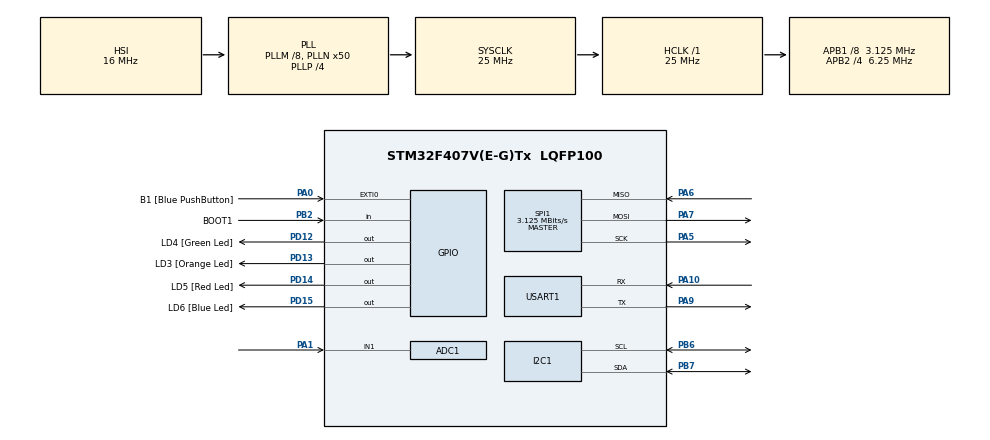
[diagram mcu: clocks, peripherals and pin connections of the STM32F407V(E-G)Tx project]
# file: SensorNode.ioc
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ADC1.Channel-0\#ChannelRegularConversion=ADC_CHANNEL_1
ADC1.NbrOfConversionFlag=1
ADC1.Rank-0\#ChannelRegularConversion=1
ADC1.SamplingTime-0\#ChannelRegularConversion=ADC_SAMPLETIME_3CYCLES
ADC1.master=1
Mcu.Family=STM32F4
Mcu.Name=STM32F407V(E-G)Tx
Mcu.Package=LQFP100
NVIC.PriorityGroup=NVIC_PRIORITYGROUP_0
PA0-WKUP.GPIO_Label=B1 [Blue PushButton]
PA0-WKUP.GPIO_ModeDefaultEXTI=GPIO_MODE_EVT_RISING
PA0-WKUP.GPIO_PuPd=GPIO_NOPULL
PA0-WKUP.Signal=GPXTI0
PA1.Signal=ADCx_IN1
PA10.Mode=Asynchronous
PA10.Signal=USART1_RX
PA13.GPIO_Label=SWDIO
PA13.Mode=Serial_Wire
PA13.Signal=SYS_JTMS-SWDIO
PA14.GPIO_Label=SWCLK
PA14.Mode=Serial_Wire
PA14.Signal=SYS_JTCK-SWCLK
PA5.Mode=Full_Duplex_Master
PA5.Signal=SPI1_SCK
PA6.Mode=Full_Duplex_Master
PA6.Signal=SPI1_MISO
PA7.Mode=Full_Duplex_Master
PA7.Signal=SPI1_MOSI
PA9.Mode=Asynchronous
PA9.Signal=USART1_TX
PB2.GPIO_Label=BOOT1
PB2.GPIO_Mode=GPIO_MODE_INPUT
PB2.GPIO_PuPd=GPIO_NOPULL
PB2.Signal=GPIO_Input
PB3.GPIO_Label=SWO
PB3.Signal=SYS_JTDO-SWO
PB6.Mode=I2C
PB6.Signal=I2C1_SCL
PB7.Mode=I2C
PB7.Signal=I2C1_SDA
PC14-OSC32_IN.GPIO_Label=PC14-OSC32_IN
PC14-OSC32_IN.Signal=RCC_OSC32_IN
PC15-OSC32_OUT.GPIO_Label=PC15-OSC32_OUT
PC15-OSC32_OUT.Signal=RCC_OSC32_OUT
PC7.GPIO_Label=I2S3_MCK [CS43L22_MCLK]
PC7.GPIO_Mode=GPIO_MODE_AF_PP
PC7.GPIO_PuPd=GPIO_NOPULL
PC7.GPIO_Speed=GPIO_SPEED_FREQ_LOW
PC7.Signal=I2S3_MCK
PD12.GPIO_Label=LD4 [Green Led]
PD12.GPIO_PuPd=GPIO_NOPULL
PD12.GPIO_Speed=GPIO_SPEED_FREQ_LOW
PD12.Signal=GPIO_Output
PD13.GPIO_Label=LD3 [Orange Led]
PD13.GPIO_PuPd=GPIO_NOPULL
PD13.GPIO_Speed=GPIO_SPEED_FREQ_LOW
PD13.Signal=GPIO_Output
PD14.GPIO_Label=LD5 [Red Led]
PD14.GPIO_PuPd=GPIO_NOPULL
PD14.GPIO_Speed=GPIO_SPEED_FREQ_LOW
PD14.Signal=GPIO_Output
PD15.GPIO_Label=LD6 [Blue Led]
PD15.GPIO_PuPd=GPIO_NOPULL
PD15.GPIO_Speed=GPIO_SPEED_FREQ_LOW
PD15.Signal=GPIO_Output
PH0-OSC_IN.GPIO_Label=PH0-OSC_IN
PH0-OSC_IN.Signal=RCC_OSC_IN
PH1-OSC_OUT.GPIO_Label=PH1-OSC_OUT
PH1-OSC_OUT.Signal=RCC_OSC_OUT
ProjectManager.HeapSize=0x2000
ProjectManager.StackSize=0x4000
ProjectManager.TargetToolchain=EWARM
RCC.48MHZClocksFreq_Value=14285714.285714285
RCC.AHBFreq_Value=25000000
RCC.APB1CLKDivider=RCC_HCLK_DIV8
RCC.APB1Freq_Value=3125000
RCC.APB1TimFreq_Value=6250000
RCC.APB2CLKDivider=RCC_HCLK_DIV4
RCC.APB2Freq_Value=6250000
RCC.APB2TimFreq_Value=12500000
RCC.CortexFreq_Value=25000000
RCC.HCLKFreq_Value=25000000
RCC.HSE_VALUE=8000000
RCC.HSI_VALUE=16000000
RCC.LSE_VALUE=32768
RCC.PLLM=8
RCC.PLLN=50
RCC.PLLP=RCC_PLLP_DIV4
RCC.PLLQ=7
RCC.SYSCLKFreq_VALUE=25000000
RCC.SYSCLKSource=RCC_SYSCLKSOURCE_PLLCLK
RCC.VCOOutputFreq_Value=100000000
SH.ADCx_IN1.0=ADC1_IN1,IN1
SPI1.CalculateBaudRate=3.125 MBits/s
SPI1.Mode=SPI_MODE_MASTER
VP_CRC_VS_CRC.Mode=CRC_Activate
board=STM32F4DISCOVERY

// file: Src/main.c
/**
  ******************************************************************************
  * File Name          : main.c
  * Description        : Main program body
  ******************************************************************************
  *
  * COPYRIGHT(c) 2017 STMicroelectronics
  *
  * Redistribution and use in source and binary forms, with or without modification,
  * are permitted provided that the following conditions are met:
  *   1. Redistributions of source code must retain the above copyright notice,
  *      this list of conditions and the following disclaimer.
  *   2. Redistributions in binary form must reproduce the above copyright notice,
  *      this list of conditions and the following disclaimer in the documentation
  *      and/or other materials provided with the distribution.
  *   3. Neither the name of STMicroelectronics nor the names of its contributors
  *      may be used to endorse or promote products derived from this software
  *      without specific prior written permission.
  *
  * THIS SOFTWARE IS PROVIDED BY THE COPYRIGHT HOLDERS AND CONTRIBUTORS "AS IS"
  * AND ANY EXPRESS OR IMPLIED WARRANTIES, INCLUDING, BUT NOT LIMITED TO, THE
  * IMPLIED WARRANTIES OF MERCHANTABILITY AND FITNESS FOR A PARTICULAR PURPOSE ARE
  * DISCLAIMED. IN NO EVENT SHALL THE COPYRIGHT HOLDER OR CONTRIBUTORS BE LIABLE
  * FOR ANY DIRECT, INDIRECT, INCIDENTAL, SPECIAL, EXEMPLARY, OR CONSEQUENTIAL
  * DAMAGES (INCLUDING, BUT NOT LIMITED TO, PROCUREMENT OF SUBSTITUTE GOODS OR
  * SERVICES; LOSS OF USE, DATA, OR PROFITS; OR BUSINESS INTERRUPTION) HOWEVER
  * CAUSED AND ON ANY THEORY OF LIABILITY, WHETHER IN CONTRACT, STRICT LIABILITY,
  * OR TORT (INCLUDING NEGLIGENCE OR OTHERWISE) ARISING IN ANY WAY OUT OF THE USE
  * OF THIS SOFTWARE, EVEN IF ADVISED OF THE POSSIBILITY OF SUCH DAMAGE.
  *
  ******************************************************************************
  */
#include "main.h"
#include "stm32f4xx_hal.h"
#include "adc.h"
#include "crc.h"
#include "i2c.h"
#include "spi.h"
#include "usart.h"
#include "gpio.h"

/* USER CODE BEGIN Includes */

#include "../Inc/TSL2561.h"
#include "../Inc/Si7021.h"
//#include "../Inc/PIRMotionSensor.h"

/* USER CODE END Includes */

/* USER CODE BEGIN PV */
/* Private variables ---------------------------------------------------------*/

/* USER CODE END PV */

void SystemClock_Config(void);
void Error_Handler(void);

/* USER CODE BEGIN PFP */
/* Private function prototypes -----------------------------------------------*/

/* USER CODE END PFP */

int main(void)
{

  /* MCU Configuration----------------------------------------------------------*/

  /* Reset of all peripherals, Initializes the Flash interface and the Systick. */
  HAL_Init();

  /* Configure the system clock */
  SystemClock_Config();

  /* Initialize all configured peripherals */
  MX_GPIO_Init();
  MX_ADC1_Init();
  MX_I2C1_Init();
  MX_SPI1_Init();
  MX_USART1_UART_Init();
  MX_CRC_Init();

  /* USER CODE BEGIN 2 */
	TSL2561_Init();
	Si7021_Init();
	//PIRMotionSensor_Init();

	static uint16_t count;
	count = 0;

  /* USER CODE END 2 */

  /* Infinite loop */
	while (1)
	{

  /* USER CODE BEGIN 3 */
		//Note to eslf: Find any clobbered files/code. Fix settings in cube mx

		//implement adc for microphone

	}
  /* USER CODE END 3 */

}

/** System Clock Configuration
*/
void SystemClock_Config(void)
{

  RCC_OscInitTypeDef RCC_OscInitStruct;
  RCC_ClkInitTypeDef RCC_ClkInitStruct;

    /**Configure the main internal regulator output voltage
    */
  __HAL_RCC_PWR_CLK_ENABLE();

  __HAL_PWR_VOLTAGESCALING_CONFIG(PWR_REGULATOR_VOLTAGE_SCALE1);

    /**Initializes the CPU, AHB and APB busses clocks
    */
  RCC_OscInitStruct.OscillatorType = RCC_OSCILLATORTYPE_HSI;
  RCC_OscInitStruct.HSIState = RCC_HSI_ON;
  RCC_OscInitStruct.HSICalibrationValue = 16;
  RCC_OscInitStruct.PLL.PLLState = RCC_PLL_ON;
  RCC_OscInitStruct.PLL.PLLSource = RCC_PLLSOURCE_HSI;
  RCC_OscInitStruct.PLL.PLLM = 8;
  RCC_OscInitStruct.PLL.PLLN = 50;
  RCC_OscInitStruct.PLL.PLLP = RCC_PLLP_DIV4;
  RCC_OscInitStruct.PLL.PLLQ = 7;
  if (HAL_RCC_OscConfig(&RCC_OscInitStruct) != HAL_OK)
  {
    Error_Handler();
  }

    /**Initializes the CPU, AHB and APB busses clocks
    */
  RCC_ClkInitStruct.ClockType = RCC_CLOCKTYPE_HCLK|RCC_CLOCKTYPE_SYSCLK
                              |RCC_CLOCKTYPE_PCLK1|RCC_CLOCKTYPE_PCLK2;
  RCC_ClkInitStruct.SYSCLKSource = RCC_SYSCLKSOURCE_PLLCLK;
  RCC_ClkInitStruct.AHBCLKDivider = RCC_SYSCLK_DIV1;
  RCC_ClkInitStruct.APB1CLKDivider = RCC_HCLK_DIV8;
  RCC_ClkInitStruct.APB2CLKDivider = RCC_HCLK_DIV4;

  if (HAL_RCC_ClockConfig(&RCC_ClkInitStruct, FLASH_LATENCY_0) != HAL_OK)
  {
    Error_Handler();
  }

    /**Configure the Systick interrupt time
    */
  HAL_SYSTICK_Config(HAL_RCC_GetHCLKFreq()/1000);

    /**Configure the Systick
    */
  HAL_SYSTICK_CLKSourceConfig(SYSTICK_CLKSOURCE_HCLK);

  /* SysTick_IRQn interrupt configuration */
  HAL_NVIC_SetPriority(SysTick_IRQn, 0, 0);
}

void Error_Handler(void)
{
	while(1)
	{
	}
}

/************************ (C) COPYRIGHT STMicroelectronics *****END OF FILE****/
